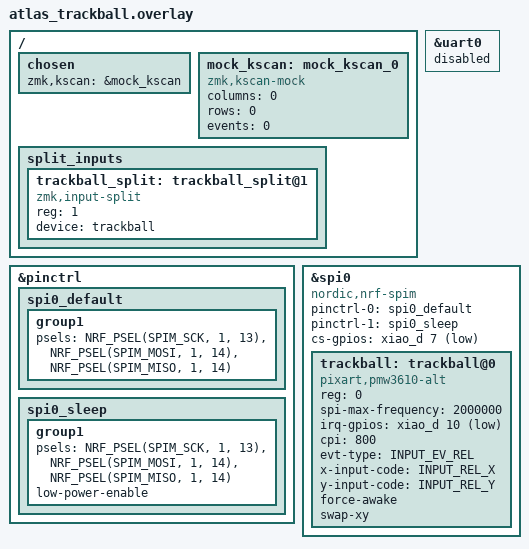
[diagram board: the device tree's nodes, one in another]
#include <dt-bindings/pinctrl/nrf-pinctrl.h>
#include <zephyr/dt-bindings/input/input-event-codes.h>

/ {
    chosen {
        zmk,kscan = &mock_kscan;
    };

    /* Mock kscan - trackball has no keyboard matrix */
    mock_kscan: mock_kscan_0 {
        compatible = "zmk,kscan-mock";
        columns = <0>;
        rows = <0>;
        events = <0>;
    };
};

&pinctrl {
    spi0_default: spi0_default {
        group1 {
            psels = <NRF_PSEL(SPIM_SCK, 1, 13)>,
                    <NRF_PSEL(SPIM_MOSI, 1, 14)>,
                    <NRF_PSEL(SPIM_MISO, 1, 14)>;
        };
    };

    spi0_sleep: spi0_sleep {
        group1 {
            psels = <NRF_PSEL(SPIM_SCK, 1, 13)>,
                    <NRF_PSEL(SPIM_MOSI, 1, 14)>,
                    <NRF_PSEL(SPIM_MISO, 1, 14)>;
            low-power-enable;
        };
    };
};

/* Disable UART to avoid pin conflicts */
&uart0 {
    status = "disabled";
};

&spi0 {
    status = "okay";
    compatible = "nordic,nrf-spim";
    pinctrl-0 = <&spi0_default>;
    pinctrl-1 = <&spi0_sleep>;
    pinctrl-names = "default", "sleep";
    cs-gpios = <&xiao_d 7 GPIO_ACTIVE_LOW>;

    trackball: trackball@0 {
        status = "okay";
        compatible = "pixart,pmw3610-alt";
        reg = <0>;
        spi-max-frequency = <2000000>;
        irq-gpios = <&xiao_d 10 (GPIO_ACTIVE_LOW | GPIO_PULL_UP)>;
        cpi = <800>;
        evt-type = <INPUT_EV_REL>;
        x-input-code = <INPUT_REL_X>;
        y-input-code = <INPUT_REL_Y>;
        force-awake;
        swap-xy;
    };
};

/ {
    /* Input split for forwarding trackball to central */
    split_inputs {
        #address-cells = <1>;
        #size-cells = <0>;

        trackball_split: trackball_split@1 {
            compatible = "zmk,input-split";
            reg = <1>;
            device = <&trackball>;
        };
    };
};
